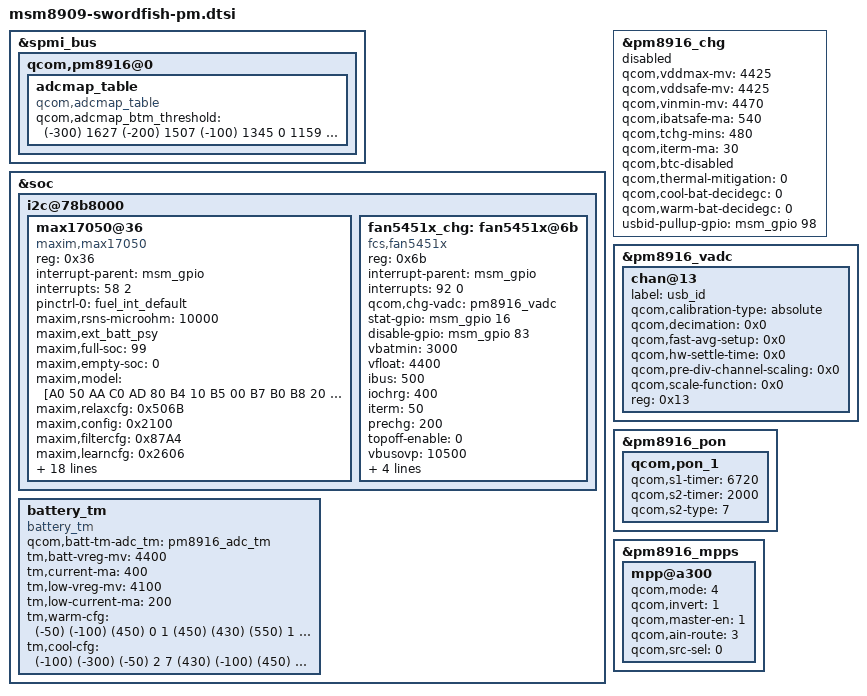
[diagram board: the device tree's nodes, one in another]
/* Copyright (c) 2016, LGE Inc. All rights reserved.
 *
 * This program is free software; you can redistribute it and/or modify
 * it under the terms of the GNU General Public License version 2 and
 * only version 2 as published by the Free Software Foundation.
 *
 * This program is distributed in the hope that it will be useful,
 * but WITHOUT ANY WARRANTY; without even the implied warranty of
 * MERCHANTABILITY or FITNESS FOR A PARTICULAR PURPOSE.  See the
 * GNU General Public License for more details.
 */

&spmi_bus {
	qcom,pm8916@0 {
		/*
		 * Since negative numbers are not allowed in device trees,
		 * the first two digits here specify if the last two are
		 * negative: 0 == positive, 1 == negative.
		 */
		adcmap_table {
			compatible = "qcom,adcmap_table";
			status = "okay";
			qcom,adcmap_btm_threshold = <
				(-300) 1627
				(-200) 1507
				(-100) 1345
				0 1159
				10 1139
				20 1120
				30 1101
				40 1082
				50 1064
				60 1045
				70 1026
				80 1008
				90 989
				100 972
				110 954
				120 936
				130 919
				140 902
				150 885
				160 869
				170 853
				180 837
				190 822
				200 807
				210 792
				220 777
				230 763
				240 750
				250 737
				260 724
				270 711
				280 699
				290 687
				300 675
				310 664
				320 653
				330 643
				340 633
				350 623
				360 613
				370 604
				380 595
				390 586
				400 578
				410 570
				420 562
				430 555
				440 547
				450 540
				460 533
				470 527
				480 521
				490 515
				500 509
				510 503
				520 498
				530 492
				540 487
				550 482
				560 478
				570 473
				580 469
				590 465
				600 461
				610 457
				620 453
				630 449
				640 446
				650 442
				660 439
				670 436
				680 433
				690 430
				700 427
				710 425
				720 422
				730 420
				740 417
				750 415
				760 413
				770 411
				780 409
				790 407>;
		};
	};
};

&soc {
	i2c@78b8000 {
		max17050@36 {
			status = "ok";
			compatible = "maxim,max17050";
			reg = <0x36>;
			interrupt-parent = <&msm_gpio>;
			interrupts = <58 2>;
			pinctrl-names = "default";
			pinctrl-0 = <&fuel_int_default>;

			maxim,rsns-microohm = <10000>;
			maxim,ext_batt_psy;
			maxim,full-soc = <99>;
			maxim,empty-soc = <0>;

			maxim,model = [A0 50 AA C0 AD 80 B4 10
					B5 00 B7 B0 B8 20 B8 90
					BC 30 BC 80 C3 40 C3 90
					CB 40 CC 80 D6 D0 D7 90
					00 C0 01 70 01 D0 04 40
					08 E0 2D B0 09 20 0C 20
					0C C0 11 20 0C C0 08 50
					06 60 06 90 0A A0 0A A0
					01 00 01 00 01 00 01 00
					01 00 01 00 01 00 01 00
					01 00 01 00 01 00 01 00
					01 00 01 00 01 00 01 00];

			maxim,relaxcfg = <0x506B>;
			maxim,config = <0x2100>;
			maxim,filtercfg = <0x87A4>;
			maxim,learncfg = <0x2606>;
			maxim,misccfg = <0x0870>;
			maxim,fullsocthr = <0x5F00>;
			maxim,rcomp0 = <0x004F>;
			maxim,tempco = <0x2F35>;
			maxim,tempnom = <0x1400>;
			maxim,tgain = <0xE932>;
			maxim,toff = <0x2381>;
			maxim,ichgterm = <0x00C0>;
			maxim,vempty = <0x964C>;
			maxim,qrtable00 = <0x0D84>;
			maxim,qrtable10 = <0x0A08>;
			maxim,qrtable20 = <0x0884>;
			maxim,qrtable30 = <0x0584>;
			maxim,capacity = <0x0320>;
			maxim,vf_fullcap = <0x0320>;
			maxim,temperature = <0x1400>;
			maxim,dpacc = <0x0C80>;
			maxim,param-version = <0x2>;
		};

		fan5451x_chg: fan5451x@6b {
			status = "ok";
			compatible = "fcs,fan5451x";
			reg = <0x6b>;
			interrupt-parent = <&msm_gpio>;
			interrupts = <92 0>;

			qcom,chg-vadc = <&pm8916_vadc>;
			stat-gpio = <&msm_gpio 16 0x00>;
			disable-gpio = <&msm_gpio 83 0x00>;

			vbatmin = <3000>;    //CC start voltage 3.0V
			vfloat = <4400>;     //vbatmax
			ibus = <500>;        //iusb for vbus
			iochrg = <400>;      //CC current
			iterm = <50>;        //term current
			prechg = <200>;      //pre charge current
			topoff-enable = <0>; //post charging flag
			vbusovp = <10500>;   //ovd for usb
			vbuslim = <4560>;    //uvd for usb
			vinovp = <10500>;    //ovd for wireless
			vinlim = <4560>;     //uvd for wireless
			fctmr = <0>;         //fast charge timer off
		};
	};

	battery_tm: battery_tm {
		compatible = "battery_tm";
		status = "ok";
		qcom,batt-tm-adc_tm = <&pm8916_adc_tm>;
		tm,batt-vreg-mv = <4400>;
		tm,current-ma = <400>;
		tm,low-vreg-mv = <4100>;
		tm,low-current-ma = <200>;
		tm,warm-cfg = <
			 (-50) (-100) (450) 0 1
			 (450)  (430) (550) 1 2
			 (550)  (430) (600) 2 2
			 (600)  (430) (790) 3 2>;
		tm,cool-cfg = <
			(-100) (-300) (-50) 2 7
			 (430) (-100) (450) 0 1>;
	};
};

&pm8916_chg {
	status = "disabled";
	qcom,vddmax-mv = <4425>;
	qcom,vddsafe-mv = <4425>;
	qcom,vinmin-mv = <4470>;
	qcom,ibatsafe-ma = <540>;
	qcom,tchg-mins = <480>;
	qcom,iterm-ma = <30>;
	qcom,btc-disabled;
	qcom,thermal-mitigation = <0>; /* disabled */
	qcom,cool-bat-decidegc = <0>;  /* disabled */
	qcom,warm-bat-decidegc = <0>;  /* disabled */
	usbid-pullup-gpio = <&msm_gpio 98 0x00>;
};

&pm8916_vadc {
	chan@13 {
		label = "usb_id";
		qcom,calibration-type = "absolute";
		qcom,decimation = <0x0>;
		qcom,fast-avg-setup = <0x0>;
		qcom,hw-settle-time = <0x0>;
		qcom,pre-div-channel-scaling = <0x0>;
		qcom,scale-function = <0x0>;
		reg = <0x13>;
	};
};

&pm8916_pon {
	qcom,pon_1 {
		qcom,s1-timer = <6720>;
		qcom,s2-timer = <2000>;
		qcom,s2-type = <7>;
	};
};

&pm8916_mpps {
	mpp@a300 { // MPP 4 For PM_USB_ID ADC
		qcom,mode = <4>;      // MODE_CTL: ANALOG_INPUT
		qcom,invert = <1>;    // MODE_CTL: ANALOG Enable
		qcom,master-en = <1>; // EN_CTL: MPP Enabled
		qcom,ain-route = <3>; // ANA_IN_CTL: HKADC8
		qcom,src-sel = <0>;   // MODE_CTL: Source 0
	};
};
